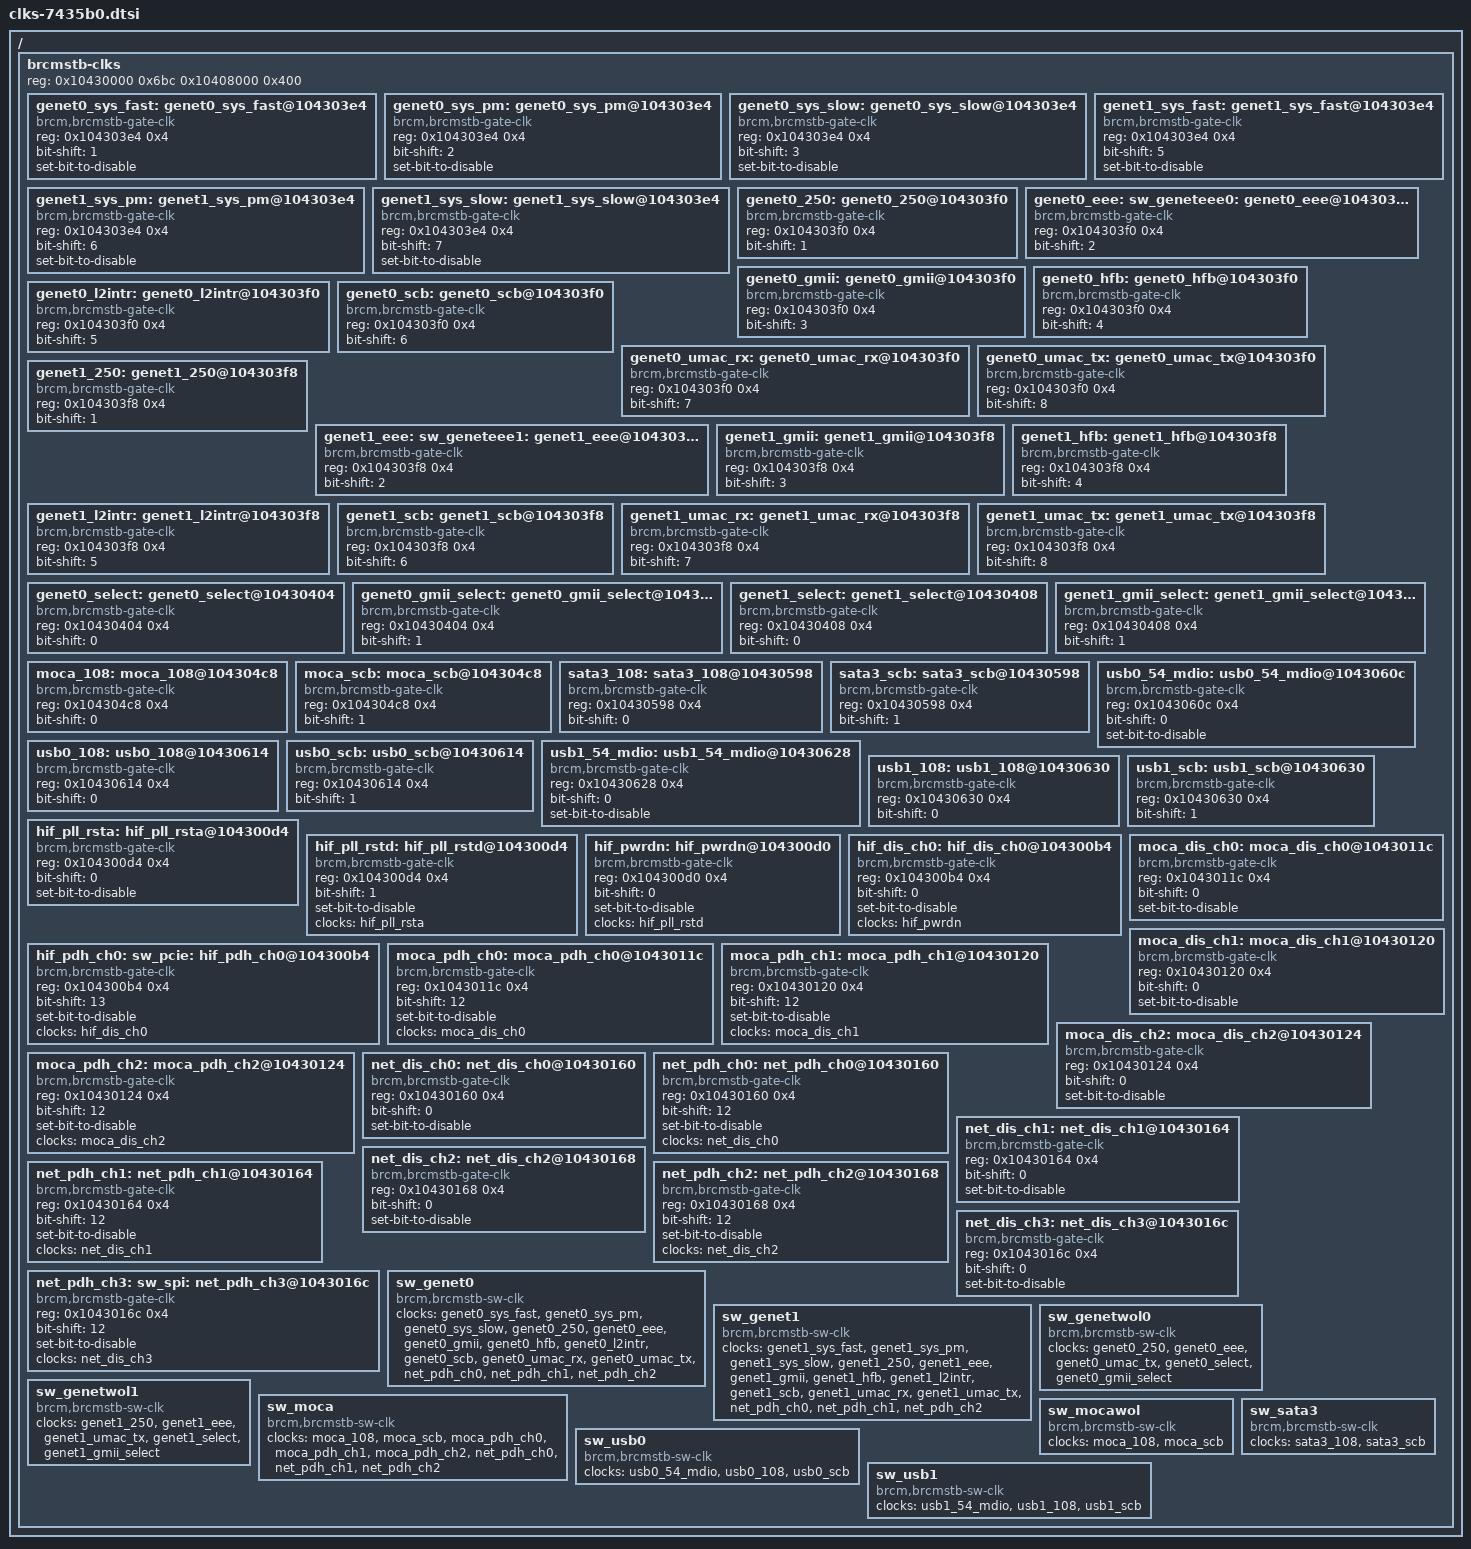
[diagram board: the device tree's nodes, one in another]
/*
	'rdb_sha1' => 'KgdjmypotQ/ULvSrAa37pf9CCmo',
	'fail' => 0,
	'date' => 'Thu Mar  2 13:27:59 PST 2017',
	'rdb_version' => 'rdb-v2-50-g0ea4e50',
	'rdb_dir' => '/projects/stbgit/stblinux/git/clkgen/7435b0/current',
	'clkgen_version' => 'clkgen-v4-283-g9f403e5-dirty',
	'pm_ver' => '???',
	'chip' => '7435b0',
	'aliases' => {},
	'unhandled_linux_funcs' => '',
	'invocation' => 'clkgen.pl --sw_nodes -v -g -r -P -c 7435b0',
	'num_clks' => 64,
*/

/ {
	brcmstb-clks {
		#address-cells = <1>;
		#size-cells = <1>;
		reg = <0x10430000 0x6bc 0x10408000 0x400>;
		ranges;

		genet0_sys_fast: genet0_sys_fast@104303e4 {
			compatible = "brcm,brcmstb-gate-clk";
			#clock-cells = <0>;
			reg = <0x104303e4 0x4>;
			bit-shift = <1>;
			set-bit-to-disable;
		};

		genet0_sys_pm: genet0_sys_pm@104303e4 {
			compatible = "brcm,brcmstb-gate-clk";
			#clock-cells = <0>;
			reg = <0x104303e4 0x4>;
			bit-shift = <2>;
			set-bit-to-disable;
		};

		genet0_sys_slow: genet0_sys_slow@104303e4 {
			compatible = "brcm,brcmstb-gate-clk";
			#clock-cells = <0>;
			reg = <0x104303e4 0x4>;
			bit-shift = <3>;
			set-bit-to-disable;
		};

		genet1_sys_fast: genet1_sys_fast@104303e4 {
			compatible = "brcm,brcmstb-gate-clk";
			#clock-cells = <0>;
			reg = <0x104303e4 0x4>;
			bit-shift = <5>;
			set-bit-to-disable;
		};

		genet1_sys_pm: genet1_sys_pm@104303e4 {
			compatible = "brcm,brcmstb-gate-clk";
			#clock-cells = <0>;
			reg = <0x104303e4 0x4>;
			bit-shift = <6>;
			set-bit-to-disable;
		};

		genet1_sys_slow: genet1_sys_slow@104303e4 {
			compatible = "brcm,brcmstb-gate-clk";
			#clock-cells = <0>;
			reg = <0x104303e4 0x4>;
			bit-shift = <7>;
			set-bit-to-disable;
		};

		genet0_250: genet0_250@104303f0 {
			compatible = "brcm,brcmstb-gate-clk";
			#clock-cells = <0>;
			reg = <0x104303f0 0x4>;
			bit-shift = <1>;
		};

		genet0_eee: sw_geneteee0: genet0_eee@104303f0 {
			compatible = "brcm,brcmstb-gate-clk";
			#clock-cells = <0>;
			reg = <0x104303f0 0x4>;
			bit-shift = <2>;
		};

		genet0_gmii: genet0_gmii@104303f0 {
			compatible = "brcm,brcmstb-gate-clk";
			#clock-cells = <0>;
			reg = <0x104303f0 0x4>;
			bit-shift = <3>;
		};

		genet0_hfb: genet0_hfb@104303f0 {
			compatible = "brcm,brcmstb-gate-clk";
			#clock-cells = <0>;
			reg = <0x104303f0 0x4>;
			bit-shift = <4>;
		};

		genet0_l2intr: genet0_l2intr@104303f0 {
			compatible = "brcm,brcmstb-gate-clk";
			#clock-cells = <0>;
			reg = <0x104303f0 0x4>;
			bit-shift = <5>;
		};

		genet0_scb: genet0_scb@104303f0 {
			compatible = "brcm,brcmstb-gate-clk";
			#clock-cells = <0>;
			reg = <0x104303f0 0x4>;
			bit-shift = <6>;
		};

		genet0_umac_rx: genet0_umac_rx@104303f0 {
			compatible = "brcm,brcmstb-gate-clk";
			#clock-cells = <0>;
			reg = <0x104303f0 0x4>;
			bit-shift = <7>;
		};

		genet0_umac_tx: genet0_umac_tx@104303f0 {
			compatible = "brcm,brcmstb-gate-clk";
			#clock-cells = <0>;
			reg = <0x104303f0 0x4>;
			bit-shift = <8>;
		};

		genet1_250: genet1_250@104303f8 {
			compatible = "brcm,brcmstb-gate-clk";
			#clock-cells = <0>;
			reg = <0x104303f8 0x4>;
			bit-shift = <1>;
		};

		genet1_eee: sw_geneteee1: genet1_eee@104303f8 {
			compatible = "brcm,brcmstb-gate-clk";
			#clock-cells = <0>;
			reg = <0x104303f8 0x4>;
			bit-shift = <2>;
		};

		genet1_gmii: genet1_gmii@104303f8 {
			compatible = "brcm,brcmstb-gate-clk";
			#clock-cells = <0>;
			reg = <0x104303f8 0x4>;
			bit-shift = <3>;
		};

		genet1_hfb: genet1_hfb@104303f8 {
			compatible = "brcm,brcmstb-gate-clk";
			#clock-cells = <0>;
			reg = <0x104303f8 0x4>;
			bit-shift = <4>;
		};

		genet1_l2intr: genet1_l2intr@104303f8 {
			compatible = "brcm,brcmstb-gate-clk";
			#clock-cells = <0>;
			reg = <0x104303f8 0x4>;
			bit-shift = <5>;
		};

		genet1_scb: genet1_scb@104303f8 {
			compatible = "brcm,brcmstb-gate-clk";
			#clock-cells = <0>;
			reg = <0x104303f8 0x4>;
			bit-shift = <6>;
		};

		genet1_umac_rx: genet1_umac_rx@104303f8 {
			compatible = "brcm,brcmstb-gate-clk";
			#clock-cells = <0>;
			reg = <0x104303f8 0x4>;
			bit-shift = <7>;
		};

		genet1_umac_tx: genet1_umac_tx@104303f8 {
			compatible = "brcm,brcmstb-gate-clk";
			#clock-cells = <0>;
			reg = <0x104303f8 0x4>;
			bit-shift = <8>;
		};

		genet0_select: genet0_select@10430404 {
			compatible = "brcm,brcmstb-gate-clk";
			#clock-cells = <0>;
			reg = <0x10430404 0x4>;
			bit-shift = <0>;
		};

		genet0_gmii_select: genet0_gmii_select@10430404 {
			compatible = "brcm,brcmstb-gate-clk";
			#clock-cells = <0>;
			reg = <0x10430404 0x4>;
			bit-shift = <1>;
		};

		genet1_select: genet1_select@10430408 {
			compatible = "brcm,brcmstb-gate-clk";
			#clock-cells = <0>;
			reg = <0x10430408 0x4>;
			bit-shift = <0>;
		};

		genet1_gmii_select: genet1_gmii_select@10430408 {
			compatible = "brcm,brcmstb-gate-clk";
			#clock-cells = <0>;
			reg = <0x10430408 0x4>;
			bit-shift = <1>;
		};

		moca_108: moca_108@104304c8 {
			compatible = "brcm,brcmstb-gate-clk";
			#clock-cells = <0>;
			reg = <0x104304c8 0x4>;
			bit-shift = <0>;
		};

		moca_scb: moca_scb@104304c8 {
			compatible = "brcm,brcmstb-gate-clk";
			#clock-cells = <0>;
			reg = <0x104304c8 0x4>;
			bit-shift = <1>;
		};

		sata3_108: sata3_108@10430598 {
			compatible = "brcm,brcmstb-gate-clk";
			#clock-cells = <0>;
			reg = <0x10430598 0x4>;
			bit-shift = <0>;
		};

		sata3_scb: sata3_scb@10430598 {
			compatible = "brcm,brcmstb-gate-clk";
			#clock-cells = <0>;
			reg = <0x10430598 0x4>;
			bit-shift = <1>;
		};

		usb0_54_mdio: usb0_54_mdio@1043060c {
			compatible = "brcm,brcmstb-gate-clk";
			#clock-cells = <0>;
			reg = <0x1043060c 0x4>;
			bit-shift = <0>;
			set-bit-to-disable;
		};

		usb0_108: usb0_108@10430614 {
			compatible = "brcm,brcmstb-gate-clk";
			#clock-cells = <0>;
			reg = <0x10430614 0x4>;
			bit-shift = <0>;
		};

		usb0_scb: usb0_scb@10430614 {
			compatible = "brcm,brcmstb-gate-clk";
			#clock-cells = <0>;
			reg = <0x10430614 0x4>;
			bit-shift = <1>;
		};

		usb1_54_mdio: usb1_54_mdio@10430628 {
			compatible = "brcm,brcmstb-gate-clk";
			#clock-cells = <0>;
			reg = <0x10430628 0x4>;
			bit-shift = <0>;
			set-bit-to-disable;
		};

		usb1_108: usb1_108@10430630 {
			compatible = "brcm,brcmstb-gate-clk";
			#clock-cells = <0>;
			reg = <0x10430630 0x4>;
			bit-shift = <0>;
		};

		usb1_scb: usb1_scb@10430630 {
			compatible = "brcm,brcmstb-gate-clk";
			#clock-cells = <0>;
			reg = <0x10430630 0x4>;
			bit-shift = <1>;
		};

		hif_pll_rsta: hif_pll_rsta@104300d4 {
			compatible = "brcm,brcmstb-gate-clk";
			#clock-cells = <0>;
			reg = <0x104300d4 0x4>;
			bit-shift = <0>;
			set-bit-to-disable;
		};

		hif_pll_rstd: hif_pll_rstd@104300d4 {
			compatible = "brcm,brcmstb-gate-clk";
			#clock-cells = <0>;
			reg = <0x104300d4 0x4>;
			bit-shift = <1>;
			set-bit-to-disable;
			clocks = <&hif_pll_rsta>;
			clock-names = "hif_pll_rsta";
		};

		hif_pwrdn: hif_pwrdn@104300d0 {
			compatible = "brcm,brcmstb-gate-clk";
			#clock-cells = <0>;
			reg = <0x104300d0 0x4>;
			bit-shift = <0>;
			set-bit-to-disable;
			clocks = <&hif_pll_rstd>;
			clock-names = "hif_pll_rstd";
		};

		hif_dis_ch0: hif_dis_ch0@104300b4 {
			compatible = "brcm,brcmstb-gate-clk";
			#clock-cells = <0>;
			reg = <0x104300b4 0x4>;
			bit-shift = <0>;
			set-bit-to-disable;
			clocks = <&hif_pwrdn>;
			clock-names = "hif_pwrdn";
		};

		hif_pdh_ch0: sw_pcie: hif_pdh_ch0@104300b4 {
			compatible = "brcm,brcmstb-gate-clk";
			#clock-cells = <0>;
			reg = <0x104300b4 0x4>;
			bit-shift = <13>;
			set-bit-to-disable;
			clocks = <&hif_dis_ch0>;
			clock-names = "hif_dis_ch0";
		};

		moca_dis_ch0: moca_dis_ch0@1043011c {
			compatible = "brcm,brcmstb-gate-clk";
			#clock-cells = <0>;
			reg = <0x1043011c 0x4>;
			bit-shift = <0>;
			set-bit-to-disable;
		};

		moca_pdh_ch0: moca_pdh_ch0@1043011c {
			compatible = "brcm,brcmstb-gate-clk";
			#clock-cells = <0>;
			reg = <0x1043011c 0x4>;
			bit-shift = <12>;
			set-bit-to-disable;
			clocks = <&moca_dis_ch0>;
			clock-names = "moca_dis_ch0";
		};

		moca_dis_ch1: moca_dis_ch1@10430120 {
			compatible = "brcm,brcmstb-gate-clk";
			#clock-cells = <0>;
			reg = <0x10430120 0x4>;
			bit-shift = <0>;
			set-bit-to-disable;
		};

		moca_pdh_ch1: moca_pdh_ch1@10430120 {
			compatible = "brcm,brcmstb-gate-clk";
			#clock-cells = <0>;
			reg = <0x10430120 0x4>;
			bit-shift = <12>;
			set-bit-to-disable;
			clocks = <&moca_dis_ch1>;
			clock-names = "moca_dis_ch1";
		};

		moca_dis_ch2: moca_dis_ch2@10430124 {
			compatible = "brcm,brcmstb-gate-clk";
			#clock-cells = <0>;
			reg = <0x10430124 0x4>;
			bit-shift = <0>;
			set-bit-to-disable;
		};

		moca_pdh_ch2: moca_pdh_ch2@10430124 {
			compatible = "brcm,brcmstb-gate-clk";
			#clock-cells = <0>;
			reg = <0x10430124 0x4>;
			bit-shift = <12>;
			set-bit-to-disable;
			clocks = <&moca_dis_ch2>;
			clock-names = "moca_dis_ch2";
		};

		net_dis_ch0: net_dis_ch0@10430160 {
			compatible = "brcm,brcmstb-gate-clk";
			#clock-cells = <0>;
			reg = <0x10430160 0x4>;
			bit-shift = <0>;
			set-bit-to-disable;
		};

		net_pdh_ch0: net_pdh_ch0@10430160 {
			compatible = "brcm,brcmstb-gate-clk";
			#clock-cells = <0>;
			reg = <0x10430160 0x4>;
			bit-shift = <12>;
			set-bit-to-disable;
			clocks = <&net_dis_ch0>;
			clock-names = "net_dis_ch0";
		};

		net_dis_ch1: net_dis_ch1@10430164 {
			compatible = "brcm,brcmstb-gate-clk";
			#clock-cells = <0>;
			reg = <0x10430164 0x4>;
			bit-shift = <0>;
			set-bit-to-disable;
		};

		net_pdh_ch1: net_pdh_ch1@10430164 {
			compatible = "brcm,brcmstb-gate-clk";
			#clock-cells = <0>;
			reg = <0x10430164 0x4>;
			bit-shift = <12>;
			set-bit-to-disable;
			clocks = <&net_dis_ch1>;
			clock-names = "net_dis_ch1";
		};

		net_dis_ch2: net_dis_ch2@10430168 {
			compatible = "brcm,brcmstb-gate-clk";
			#clock-cells = <0>;
			reg = <0x10430168 0x4>;
			bit-shift = <0>;
			set-bit-to-disable;
		};

		net_pdh_ch2: net_pdh_ch2@10430168 {
			compatible = "brcm,brcmstb-gate-clk";
			#clock-cells = <0>;
			reg = <0x10430168 0x4>;
			bit-shift = <12>;
			set-bit-to-disable;
			clocks = <&net_dis_ch2>;
			clock-names = "net_dis_ch2";
		};

		net_dis_ch3: net_dis_ch3@1043016c {
			compatible = "brcm,brcmstb-gate-clk";
			#clock-cells = <0>;
			reg = <0x1043016c 0x4>;
			bit-shift = <0>;
			set-bit-to-disable;
		};

		net_pdh_ch3: sw_spi: net_pdh_ch3@1043016c {
			compatible = "brcm,brcmstb-gate-clk";
			#clock-cells = <0>;
			reg = <0x1043016c 0x4>;
			bit-shift = <12>;
			set-bit-to-disable;
			clocks = <&net_dis_ch3>;
			clock-names = "net_dis_ch3";
		};

		sw_genet0: sw_genet0 {
			compatible = "brcm,brcmstb-sw-clk";
			#clock-cells = <0>;
			clocks = <&genet0_sys_fast>, <&genet0_sys_pm>,
			  <&genet0_sys_slow>, <&genet0_250>, <&genet0_eee>,
			  <&genet0_gmii>, <&genet0_hfb>, <&genet0_l2intr>,
			  <&genet0_scb>, <&genet0_umac_rx>, <&genet0_umac_tx>,
			  <&net_pdh_ch0>, <&net_pdh_ch1>, <&net_pdh_ch2>;
			clock-names = "genet0_sys_fast", "genet0_sys_pm",
			  "genet0_sys_slow", "genet0_250", "genet0_eee",
			  "genet0_gmii", "genet0_hfb", "genet0_l2intr",
			  "genet0_scb", "genet0_umac_rx", "genet0_umac_tx",
			  "net_pdh_ch0", "net_pdh_ch1", "net_pdh_ch2";
		};

		sw_genet1: sw_genet1 {
			compatible = "brcm,brcmstb-sw-clk";
			#clock-cells = <0>;
			clocks = <&genet1_sys_fast>, <&genet1_sys_pm>,
			  <&genet1_sys_slow>, <&genet1_250>, <&genet1_eee>,
			  <&genet1_gmii>, <&genet1_hfb>, <&genet1_l2intr>,
			  <&genet1_scb>, <&genet1_umac_rx>, <&genet1_umac_tx>,
			  <&net_pdh_ch0>, <&net_pdh_ch1>, <&net_pdh_ch2>;
			clock-names = "genet1_sys_fast", "genet1_sys_pm",
			  "genet1_sys_slow", "genet1_250", "genet1_eee",
			  "genet1_gmii", "genet1_hfb", "genet1_l2intr",
			  "genet1_scb", "genet1_umac_rx", "genet1_umac_tx",
			  "net_pdh_ch0", "net_pdh_ch1", "net_pdh_ch2";
		};

		sw_genetwol0: sw_genetwol0 {
			compatible = "brcm,brcmstb-sw-clk";
			#clock-cells = <0>;
			clocks = <&genet0_250>, <&genet0_eee>,
			  <&genet0_umac_tx>, <&genet0_select>,
			  <&genet0_gmii_select>;
			clock-names = "genet0_250", "genet0_eee",
			  "genet0_umac_tx", "genet0_select",
			  "genet0_gmii_select";
		};

		sw_genetwol1: sw_genetwol1 {
			compatible = "brcm,brcmstb-sw-clk";
			#clock-cells = <0>;
			clocks = <&genet1_250>, <&genet1_eee>,
			  <&genet1_umac_tx>, <&genet1_select>,
			  <&genet1_gmii_select>;
			clock-names = "genet1_250", "genet1_eee",
			  "genet1_umac_tx", "genet1_select",
			  "genet1_gmii_select";
		};

		sw_moca: sw_moca {
			compatible = "brcm,brcmstb-sw-clk";
			#clock-cells = <0>;
			clocks = <&moca_108>, <&moca_scb>, <&moca_pdh_ch0>,
			  <&moca_pdh_ch1>, <&moca_pdh_ch2>, <&net_pdh_ch0>,
			  <&net_pdh_ch1>, <&net_pdh_ch2>;
			clock-names = "moca_108", "moca_scb", "moca_pdh_ch0",
			  "moca_pdh_ch1", "moca_pdh_ch2", "net_pdh_ch0",
			  "net_pdh_ch1", "net_pdh_ch2";
		};

		sw_mocawol: sw_mocawol {
			compatible = "brcm,brcmstb-sw-clk";
			#clock-cells = <0>;
			clocks = <&moca_108>, <&moca_scb>;
			clock-names = "moca_108", "moca_scb";
		};

		sw_sata3: sw_sata3 {
			compatible = "brcm,brcmstb-sw-clk";
			#clock-cells = <0>;
			clocks = <&sata3_108>, <&sata3_scb>;
			clock-names = "sata3_108", "sata3_scb";
		};

		sw_usb0: sw_usb0 {
			compatible = "brcm,brcmstb-sw-clk";
			#clock-cells = <0>;
			clocks = <&usb0_54_mdio>, <&usb0_108>, <&usb0_scb>;
			clock-names = "usb0_54_mdio", "usb0_108", "usb0_scb";
		};

		sw_usb1: sw_usb1 {
			compatible = "brcm,brcmstb-sw-clk";
			#clock-cells = <0>;
			clocks = <&usb1_54_mdio>, <&usb1_108>, <&usb1_scb>;
			clock-names = "usb1_54_mdio", "usb1_108", "usb1_scb";
		};

	};

};
